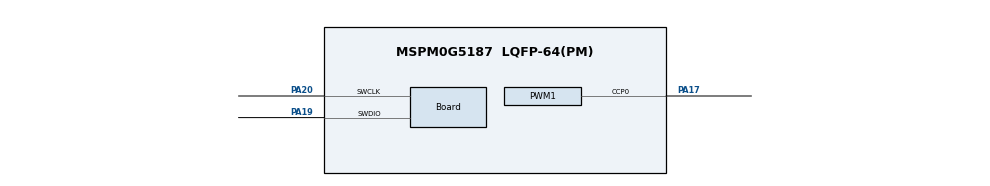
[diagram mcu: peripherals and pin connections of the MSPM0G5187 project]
//@cliArgs --device "MSPM0G518X" --package "LQFP-64(PM)" --part "Default"
//@v2CliArgs --device "MSPM0G5187" --package "LQFP-64(PM)"
// @cliArgs --board /ti/boards/LP_MSPM0G5187 --rtos nortos

/**
 * Import the modules used in this configuration.
 */
const ADC12  = scripting.addModule("/ti/driverlib/ADC12", {}, false);
const ADC121 = ADC12.addInstance();
const PWM    = scripting.addModule("/ti/driverlib/PWM", {}, false);
const PWM1   = PWM.addInstance();
const SYSCTL = scripting.addModule("/ti/driverlib/SYSCTL");
const TIMER  = scripting.addModule("/ti/driverlib/TIMER", {}, false);
const TIMER1 = TIMER.addInstance();

/**
 * Write custom configuration values to the imported modules.
 */
ADC121.$name                      = "ADC12_0";
ADC121.sampClkSrc                 = "DL_ADC12_CLOCK_ULPCLK";
ADC121.trigSrc                    = "DL_ADC12_TRIG_SRC_EVENT";
ADC121.sampleTime0                = "25 us";
ADC121.enabledInterrupts          = ["DL_ADC12_INTERRUPT_MEM0_RESULT_LOADED"];
ADC121.subChanID                  = 1;
ADC121.adcMem0chansel             = "DL_ADC12_INPUT_CHAN_2";
ADC121.peripheral.$assign         = "ADC0";
ADC121.peripheral.adcPin2.$assign = "PA25";
ADC121.adcPin2Config.$name        = "ti_driverlib_gpio_GPIOPinGeneric0";

const Board                       = scripting.addModule("/ti/driverlib/Board", {}, false);
Board.peripheral.$assign          = "DEBUGSS";
Board.peripheral.swclkPin.$assign = "PA20";
Board.peripheral.swdioPin.$assign = "PA19";

PWM1.$name                      = "PWM_0";
PWM1.ccIndex                    = [0];
PWM1.clockDivider               = 8;
PWM1.enableShadowLoad           = true;
PWM1.PWM_CHANNEL_0.$name        = "ti_driverlib_pwm_PWMTimerCC0";
PWM1.PWM_CHANNEL_0.dutyCycle    = 50;
PWM1.peripheral.$assign         = "TIMG7";
PWM1.peripheral.ccp0Pin.$assign = "PA17";

SYSCTL.forceDefaultClkConfig = true;
SYSCTL.peripheral.$assign    = "SYSCTL";

TIMER1.$name                       = "TIMER_0";
TIMER1.timerClkSrc                 = "LFCLK";
TIMER1.timerMode                   = "PERIODIC";
TIMER1.timerPeriod                 = "500 ms";
TIMER1.event1PublisherChannel      = 1;
TIMER1.event1ControllerInterruptEn = ["ZERO_EVENT"];
TIMER1.peripheral.$assign          = "TIMG0";

const ProjectConfig              = scripting.addModule("/ti/project_config/ProjectConfig", {}, false);
ProjectConfig.migrationCondition = true;
